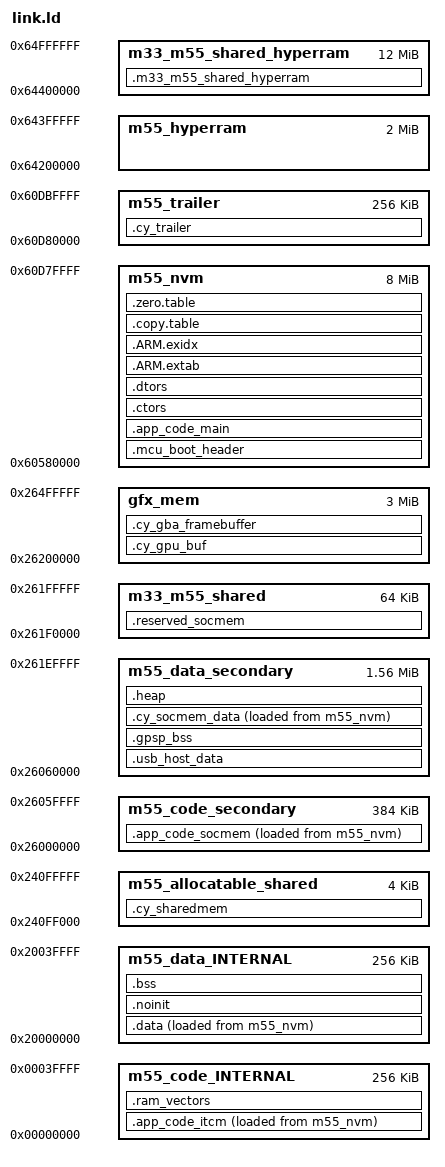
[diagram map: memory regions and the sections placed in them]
/***************************************************************************//**
* \file pse84_ns_cm55.ld
* \version 1.0.0
*
* Linker file for the GNU C compiler.
*
* The main purpose of the linker script is to describe how the sections in the
* input files should be mapped into the output file, and to control the memory
* layout of the output file.
*
*
* \note The linker files included with the PDL template projects must be generic
* and handle all common use cases. Your project may not use every section
* defined in the linker files. In that case you may see warnings during the
* build process. In your project, you can simply comment out or remove the
* relevant code in the linker file.
*
********************************************************************************
* \copyright
* Copyright (c) (2020-2025), Cypress Semiconductor Corporation (an Infineon company) or
* an affiliate of Cypress Semiconductor Corporation.
* SPDX-License-Identifier: Apache-2.0
*
* Licensed under the Apache License, Version 2.0 (the "License");
* you may not use this file except in compliance with the License.
* You may obtain a copy of the License at
*
*     http://www.apache.org/licenses/LICENSE-2.0
*
* Unless required by applicable law or agreed to in writing, software
* distributed under the License is distributed on an "AS IS" BASIS,
* WITHOUT WARRANTIES OR CONDITIONS OF ANY KIND, either express or implied.
* See the License for the specific language governing permissions and
* limitations under the License.
*******************************************************************************/
/* Specify the output format for the linker script */
OUTPUT_FORMAT ("elf32-littlearm", "elf32-bigarm", "elf32-littlearm")
/* Search for libraries in the current directory */
SEARCH_DIR(.)
/* Specify the group of libraries to link against */
GROUP(-lgcc -lc -lnosys)
GROUP(libgcc.a libc.a libm.a libnosys.a)
/* Define the entry point of the program, which is the reset handler */
ENTRY(Reset_Handler)

/* Define the stack size for the application */
/* To set stack size in application add makefile ldflags: -Wl,--defsym=APP_MSP_STACK_SIZE=<CUSTOM_VALUE> */
PROVIDE(__StackSize = DEFINED(APP_MSP_STACK_SIZE) ? APP_MSP_STACK_SIZE : 0x1000);

/* Include the device memory definitions generated by the Device Configurator */
/* This file is automatically generated. */

MEMORY
{
    m55_data_INTERNAL : ORIGIN = 0x20000000, LENGTH = 0x00040000
    m55_code_INTERNAL : ORIGIN = 0x00000000, LENGTH = 0x00040000
    m55_nvm : ORIGIN = 0x60580000, LENGTH = 0x00800000
    m55_trailer : ORIGIN = 0x60D80000, LENGTH = 0x00040000
    m55_hyperram : ORIGIN = 0x64200000, LENGTH = 0x00200000
    m33_m55_shared_hyperram : ORIGIN = 0x64400000, LENGTH = 0x00C00000
    m55_code_secondary : ORIGIN = 0x26000000, LENGTH = 0x00060000
    /* M33_Template has no .cy_shared_socmem payload. Keep a conservative
       64 KiB inter-core window and return 192 KiB to the M55 SOC heap. */
    m55_data_secondary : ORIGIN = 0x26060000, LENGTH = 0x00190000
    m33_m55_shared : ORIGIN = 0x261F0000, LENGTH = 0x00010000
    gfx_mem : ORIGIN = 0x26200000, LENGTH = 0x00300000
    m55_allocatable_shared : ORIGIN = 0x240FF000, LENGTH = 0x00001000
}

REGION_ALIAS("m55_data_sel", m55_data_INTERNAL)
REGION_ALIAS("m55_code_sel", m55_code_INTERNAL)
REGION_ALIAS("m55_nvm_sel", m55_nvm)
REGION_ALIAS("m55_trailer_sel", m55_trailer)
REGION_ALIAS("m55_code_secondary_sel", m55_code_secondary)
REGION_ALIAS("m55_data_secondary_sel", m55_data_secondary)
REGION_ALIAS("m33_m55_shared_sel", m33_m55_shared)
REGION_ALIAS("gfx_mem_sel", gfx_mem)
REGION_ALIAS("m55_allocatable_shared_sel", m55_allocatable_shared)
REGION_ALIAS("m55_hyperram_sel", m55_hyperram)
REGION_ALIAS("m33_m55_shared_hyperram_sel", m33_m55_shared_hyperram)


/* Linker script to place sections and symbol values. Should be used together
 * with other linker script that defines memory regions FLASH and RAM.
 * It references following symbols, which must be defined in code:
 *   Reset_Handler : Entry of reset handler
 *
 * It defines following symbols, which code can use without definition:
 *   __exidx_start
 *   __exidx_end
 *   __copy_table_start__
 *   __copy_table_end__
 *   __zero_table_start__
 *   __zero_table_end__
 *   __data_start__
 *   __preinit_array_start
 *   __preinit_array_end
 *   __init_array_start
 *   __init_array_end
 *   __fini_array_start
 *   __fini_array_end
 *   __data_end__
 *   __bss_start__
 *   __bss_end__
 *   __end__
 *   end
 *   __HeapLimit
 *   __StackLimit
 *   __StackTop
 *   __stack
 */

/* Device definitions */
VECTORS_ALIGNMENT = 0x400;

/* The size of the MCU boot header area at the start of main code region */
MCUBOOT_HEADER_SIZE = 0x400;

/* Define the sections */
SECTIONS
{
    /* This section reserves a space for MCUBoot header */
    .mcu_boot_header :
    {
        . = ALIGN(MCUBOOT_HEADER_SIZE);
        . += MCUBOOT_HEADER_SIZE;
    } > m55_nvm_sel

    /* This section is intended to hold the main application code for the Cortex-M55 */
    /* Performance-sensitive or critical functions that need to be executed in sram are manually excluded */
    .app_code_main :
    {
        . = ALIGN(VECTORS_ALIGNMENT);
        _stext = .;
        __text_begin = .;
        __Vectors = . ;
        /* Keep the vector table */
        KEEP(*(.vectors))

        . = ALIGN(4);

        __Vectors_End = .;

        /* Keep initializers */
        KEEP(*(.init))
        /* Keep finalizers */
        KEEP(*(.fini))
        /* Static constructors */
        *crtbegin.*(.ctors)
        *crtbegin?.*(.ctors)
        *(EXCLUDE_FILE(*crtend?.* *crtend.*) .ctors)
        *(SORT(.ctors.*))
        *(.ctors)
        /* Static destructors and atexit() */
        *crtbegin.*(.dtors)
        *crtbegin?.*(.dtors)
        *(EXCLUDE_FILE(*crtend?.* *crtend.*) .dtors)
        *(SORT(.dtors.*))
        *(.dtors)
        /* Keep gpSP initialization, ROM loading and savestate code in XIP
           flash. These sections are never used by the steady-state frame
           loop; consuming them here prevents the object-wide ITCM rules below
           from wasting tightly-coupled instruction memory. */
        *gpsp*cpu.o(
            .text.init_cpu
            .text.cpu_check_savestate
            .text.cpu_read_savestate
            .text.cpu_write_savestate
            .rodata.cpu_check_savestate.*
            .rodata._ZL15gba_header_logo
        )
        *gpsp*gba_memory.o(
            .text.rom_is_pokemon_family
            .text.gamepak_must_swap
            .text.init_gamepak_buffer
            .text.init_memory
            .text.memory_term
            .text.memory_check_savestate
            .text.memory_read_savestate
            .text.memory_write_savestate
            .text.load_gamepak
            .text.load_bios
            .rodata.rom_is_pokemon_family.*
            .rodata.memory_check_savestate.*
            .rodata.memory_read_savestate.*
            .rodata.load_gamepak.*
            .rodata.gbaover
        )
        *gpsp*sound.o(
            .text.init_sound
            .text.reset_sound
            .text.sound_check_savestate
            .text.sound_read_savestate
            .text.sound_write_savestate
            .rodata.sound_check_savestate.*
            .rodata.sound_read_savestate.*
            .rodata.sound_write_savestate.*
        )

        /* Read only code (constants) */
        *(EXCLUDE_FILE(*gpsp*cpu.o *generated?gpsp_m55*?cpu.o) .rodata .rodata.* .constdata .constdata.* .conststring .conststring.*)
        /* Exclude certain files from this section as they will be placed in RAM */
        *(EXCLUDE_FILE(*cy_syslib.* *cy_syslib_ext.* *cy_smif.* *cy_smif_memnum.* *cy_smif_memslot.* *cy_smif_sfdp.* *cy_smif_hb_flash.* *mtb_hal_memoryspi.* *mtb_serial_memory.* *freertos/Source*.* *cy_clib_support*.* *cy_mutex_pool*.* *cy_time.* *cyabs_*.* *cy_worker_thread.* *cmsis*.* *upstream?gpsp?cpu.o *generated?gpsp_m55*?cpu.o *upstream?gpsp?video.o *upstream?gpsp?gba_memory.o *upstream?gpsp?gpsp_main.o *upstream?gpsp?sound.o *upstream?gpsp?serial.o *upstream?gpsp?gbp.o) .text*)

        . = ALIGN(4);
        /* section information for utest */
        . = ALIGN(4);
        __rt_utest_tc_tab_start = .;
        KEEP(*(UtestTcTab))
        __rt_utest_tc_tab_end = .;

        /* section information for finsh shell */
        . = ALIGN(4);
        __fsymtab_start = .;
        KEEP(*(FSymTab))
        __fsymtab_end = .;
        . = ALIGN(4);
        __vsymtab_start = .;
        KEEP(*(VSymTab))
        __vsymtab_end = .;
        . = ALIGN(4);

        /* section information for modules */
        . = ALIGN(4);
        __rtmsymtab_start = .;
        KEEP(*(RTMSymTab))
        __rtmsymtab_end = .;

        /* section information for initialization */
        . = ALIGN(4);
        __rt_init_start = .;
        KEEP(*(SORT(.rti_fn*)))
        __rt_init_end = .;

        . = ALIGN(4);
        __usbh_class_info_start__ = .;
        KEEP(*(.usbh_class_info))
        __usbh_class_info_end__ = .;

        __text_end = .;
        _etext = .;
        _estack = .;
    } > m55_nvm_sel
    . = ALIGN(4);
    .ctors :
    {
        PROVIDE(__ctors_start__ = .);
        KEEP (*(SORT(.init_array.*)))
        KEEP (*(.init_array))
        PROVIDE(__ctors_end__ = .);
    } > m55_nvm_sel

    . = ALIGN(4);
    .dtors :
    {
        PROVIDE(__dtors_start__ = .);
        KEEP(*(SORT(.dtors.*)))
        KEEP(*(.dtors))
        PROVIDE(__dtors_end__ = .);
    } > m55_nvm_sel

    /* Exception tables for ARM architecture */
    .ARM.extab :
    {
        . = ALIGN(4);
        *(.ARM.extab* .gnu.linkonce.armextab.*)
    } > m55_nvm_sel

    /* Exception index tables for ARM architecture */
    .ARM.exidx :
    {
        . = ALIGN(4);
        __exidx_start = .;

        *(.ARM.exidx* .gnu.linkonce.armexidx.*)

        __exidx_end = .;
    } > m55_nvm_sel


    /* Define copying of data from flash memory to RAM during the startup */
    .copy.table :
    {
        . = ALIGN(4);
        __copy_table_start__ = .;

        /* Initialized data in DTCM */
        LONG(LOADADDR(.data))       /* From load address in ext flash  */
        LONG(ADDR(.data))           /* To run address in DTCM  */
        LONG(SIZEOF(.data)/4)       /* Size in words */

        /* Initialized data in SOC memory */
        LONG(LOADADDR(.cy_socmem_data))     /* From load address in ext flash  */
        LONG(ADDR(.cy_socmem_data))         /* To run address in SOCMEM  */
        LONG(SIZEOF(.cy_socmem_data)/4)     /* Size in words */

        /* Code in ITCM */
        LONG (LOADADDR(.app_code_itcm)) /* From load address in ext flash  */
        LONG (ADDR(.app_code_itcm))     /* To run address in ITCM  */
        LONG (SIZEOF(.app_code_itcm)/4) /* Size in words */

        /* Code in SOC memory */
        LONG (LOADADDR(.app_code_socmem)) /* From load address in ext flash  */
        LONG (ADDR(.app_code_socmem))     /* To run address in SOCMEM  */
        LONG (SIZEOF(.app_code_socmem)/4) /* Size in words */

        __copy_table_end__ = .;
    } > m55_nvm_sel

    /* Define zeroing of the uninitialized data section */
    .zero.table :
    {
        . = ALIGN(4);
        __zero_table_start__ = .;

        LONG(__bss_start__)                       /* Start of the zero-initialized data section */
        LONG((__bss_end__ - __bss_start__)/4)     /* Size of the zero-initialized data section in words */

        LONG(__usb_host_data_start__)              /* CherryUSB Host state in Secondary SRAM */
        LONG((__usb_host_data_end__ - __usb_host_data_start__)/4)

        LONG(ADDR(.gpsp_bss))                      /* gpSP interpreter state in Secondary SRAM */
        LONG(SIZEOF(.gpsp_bss)/4)

        __zero_table_end__ = .;
    } > m55_nvm_sel

    /* A section for performance-sensitive or critical functions that need to be executed in ITCM */
    .app_code_itcm :
    {
        . = ALIGN(16);
        /* Reserving the first 16 bytes to avoid debug symbols (that have default address 0x0) to be confused with actual code  */
        . += 16;
        KEEP(*(.cy_itcm))
        KEEP(*(.cy_sram_code))
        KEEP(*(.cy_ramfunc))
        KEEP(*(.text.cy_os_common))
        *cy_syslib_ext.*(.text*)
        *cy_syslib.*(.text*)
        *cy_smif.*(.text*)
        *cy_smif_memnum.*(.text*)
        *cy_smif_memslot.*(.text*)
        *cy_smif_sfdp.*(.text*)
        *cy_smif_hb_flash.*(.text*)
        *mtb_hal_memoryspi.*(.text*)
        *mtb_serial_memory.*(.text*)
        *freertos/Source*.*(.text*)
        *cy_clib_support*.*(.text*)
        *cy_mutex_pool*.*(.text*)
        *cy_time.*(.text*)
        *cyabs_*.*(.text*)
        *cy_worker_thread.*(.text*)
        *cmsis*.*(.text*)

        /* Portable gpSP interpreter hotspots. The RV32/A32 dynarec backends
           are intentionally not linked on Cortex-M55. */
        *generated?gpsp_m55*?cpu.o(.text .text.* .rodata .rodata.*)
        *gpsp*cpu.o(.text .text.* .rodata .rodata.*)
        *gpsp*video.o(.text .text.*)
        *gpsp*gpsp_main.o(.text.update_gba)
        *gpsp*gba_memory.o(.text .text.*)
        *gpsp*sound.o(.text .text.*)
        *gpsp*serial.o(.text .text.*)
        *gpsp*gbp.o(.text .text.*)

        . = ALIGN(4);
    } > m55_code_INTERNAL AT > m55_nvm_sel

    /* A section for the vector table */
    .ram_vectors (NOLOAD) :
    {
        . = ALIGN(VECTORS_ALIGNMENT);
        __ram_vectors_start__ = .;

        KEEP(*(.ram_vectors))

        __ram_vectors_end__ = .;
    } > m55_code_INTERNAL

    ASSERT(
      __ram_vectors_end__ <=
        (ORIGIN(m55_code_INTERNAL) + LENGTH(m55_code_INTERNAL) - 0x8000),
      "Retro-Go ITCM hot code must preserve at least 32 KiB."
    )

    /* A section for less performance-sensitive or critical functions that might be executed in SOC memory */
    .app_code_socmem :
    {
        . = ALIGN(4);
        KEEP(*(.cy_socmem_code))
        *gpsp*gpsp_main.o(.text .text.*)

        . = ALIGN(4);
    }  > m55_code_secondary AT > m55_nvm_sel

    /* A section for initialized data memory */
    .data :
    {
        . = ALIGN(4);
        __data_start__ = .;

        *(vtable)
        *(.data*)

        . = ALIGN(4);

        /* Array of pointers to preinit functions */
        PROVIDE_HIDDEN (__preinit_array_start = .);

        KEEP(*(.preinit_array))

        PROVIDE_HIDDEN (__preinit_array_end = .);

        . = ALIGN(4);

        /* Array of pointers to init functions */
        PROVIDE_HIDDEN (__init_array_start = .);

        KEEP(*(SORT(.init_array.*)))
        KEEP(*(.init_array))

        PROVIDE_HIDDEN (__init_array_end = .);

        . = ALIGN(4);

        /* Array of pointers to finalizer functions */

        PROVIDE_HIDDEN (__fini_array_start = .);

        KEEP(*(SORT(.fini_array.*)))
        KEEP(*(.fini_array))

        PROVIDE_HIDDEN (__fini_array_end = .);

        KEEP(*(.jcr*))

        . = ALIGN(4);

        KEEP(*(.cy_dtcm))

        . = ALIGN(4);

        __data_end__ = .;
    } > m55_data_INTERNAL AT > m55_nvm_sel

    /* A section for variables that should not be initialized during the device startup */
    .noinit (NOLOAD) :
    {
        . = ALIGN(8);
        __noinit_start__ = .;

        KEEP(*(.noinit))

        . = ALIGN(4);

        __noinit_end__ = .;
    } > m55_data_INTERNAL

    /* Keep the CherryUSB Host ABI state out of the 256 KiB DTCM. */
    .usb_host_data (NOLOAD) :
    {
        . = ALIGN(8);
        __usb_host_data_start__ = .;

        *usbh_core.o(.bss*)
        *usbh_hub.o(.bss*)
        *usbh_hid.o(.bss*)
        *libusb_hc_dwc2.a:usb_hc_dwc2.o(.bss*)

        . = ALIGN(8);
        __usb_host_data_end__ = .;
    } > m55_data_secondary

    ASSERT(
      SIZEOF(.usb_host_data) == 0 || SIZEOF(.usb_host_data) >= 0x7000,
      "CherryUSB Host state is smaller than the prebuilt DWC2 ABI expects."
    )
    ASSERT(
      SIZEOF(.usb_host_data) <= 0x10000,
      "CherryUSB Host state exceeds the 64 KiB Secondary SRAM budget."
    )

    /* Keep cold/large gpSP state in Secondary SRAM. GBA IWRAM and VRAM are
       intentionally left for the DTCM .bss section below because both are
       hot interpreter/rendering memories. */
    .gpsp_bss(NOLOAD) :
    {
        . = ALIGN(64);
        *(.bss.ewram)
        *(.bss.gamepak_backup)
        *(.bss.bios_rom)
        *(.bss.sound_buffer)
        *(.bss.noise_table15)
        *(.bss.cheats)
        *(.bss.gamepak_blk_queue)
        *(.bss._ZL17obj_priority_list)
        *(.bss._ZL18obj_priority_count)
        *(.bss._ZL15obj_alpha_count)
        *gpsp*serial_proto.o(.bss*)
        *gpsp*rfu.o(.bss*)
        . = ALIGN(64);
    } > m55_data_secondary

    ASSERT(
      SIZEOF(.gpsp_bss) <= 0x120000,
      "gpSP static state exceeds the Secondary SRAM budget."
    )

    /* A section for non-initialized data memory */
    .bss(NOLOAD) :
    {
        . = ALIGN(4);
        __bss_start__ = .;

        *(.bss*)
        *(COMMON)

        . = ALIGN(4);
        _sstack = .;

        __bss_end__ = .;
    } > m55_data_INTERNAL

    __StackTop = ORIGIN(m55_data_INTERNAL) + LENGTH(m55_data_INTERNAL);
    __StackLimit = __StackTop - __StackSize;
    PROVIDE(__stack = __StackTop);

    /* Check if .data + .noinit + .bss + stack exceeds RAM limit in region m55_data_INTERNAL */
    ASSERT(
      __StackLimit >= __bss_end__,
      "Error: m55_data_INTERNAL region overflowed with stack. Ensure that the stack size is within the available RAM."
    )
    ASSERT(
      __StackLimit >= (__bss_end__ + 0x2000),
      "Retro-Go GBA DTCM layout must preserve 8 KiB below the main stack."
    )

    /* A section for SOC memory data */
    .cy_socmem_data :
    {
        . = ALIGN(4);
        KEEP(*(.cy_socmem_data))

        . = ALIGN(4);

    }  > m55_data_secondary AT > m55_nvm_sel

    /* A section for the heap memory */
    .heap(NOLOAD) :
    {
        . = ALIGN(8);
        __HeapBase = .;
        __end__ = .;
        end = __end__;

        KEEP(*(.heap*))

        . = ORIGIN(m55_data_secondary) + LENGTH(m55_data_secondary);

        __HeapLimit = .;
    } > m55_data_secondary

    /* A section for the GPU buffer */
    .cy_gpu_buf(NOLOAD) :
    {
        KEEP(*(.cy_gpu_buf))
    } > gfx_mem

    .cy_gba_framebuffer(NOLOAD) :
    {
        . = ALIGN(64);
        __retro_go_gba_framebuffer_start__ = .;
        KEEP(*(.cy_gba_framebuffer))
        . = ALIGN(32);
        __retro_go_gba_framebuffer_end__ = .;
    } > gfx_mem

    ASSERT(
      SIZEOF(.cy_gba_framebuffer) == 0x12DE0,
      "Retro-Go GBA framebuffer cache window size changed."
    )
    ASSERT(
      ((__retro_go_gba_framebuffer_start__ & 0x1F) == 0) &&
      ((__retro_go_gba_framebuffer_end__ & 0x1F) == 0),
      "Retro-Go GBA framebuffer MPU window must be 32-byte aligned."
    )


    .reserved_socmem(NOLOAD) :
    {
        . = ORIGIN(m33_m55_shared) + LENGTH(m33_m55_shared); /* reserved SOC memory */
    } > m33_m55_shared


    /* A section for shared RAM memory where only the Cortex-M55 can allocate data but all cores can access */
    .cy_sharedmem(NOLOAD) :
    {
        . = ALIGN(4);
        KEEP(*(.cy_sharedmem))

        . = ALIGN(4);
    } > m55_allocatable_shared

    /* Reserve a trail space for the signature for the bootloader - do not place any code here */
    .cy_trailer(NOLOAD) :
    {
    } > m55_trailer_sel

    .m33_m55_shared_hyperram(NOLOAD):
    {
        KEEP(*(.m33_m55_shared_hyperram))
    } > m33_m55_shared_hyperram_sel

}
